AUTOSAR XML (schema 3.1.2)
package /Components/SWC_AFAMgtT
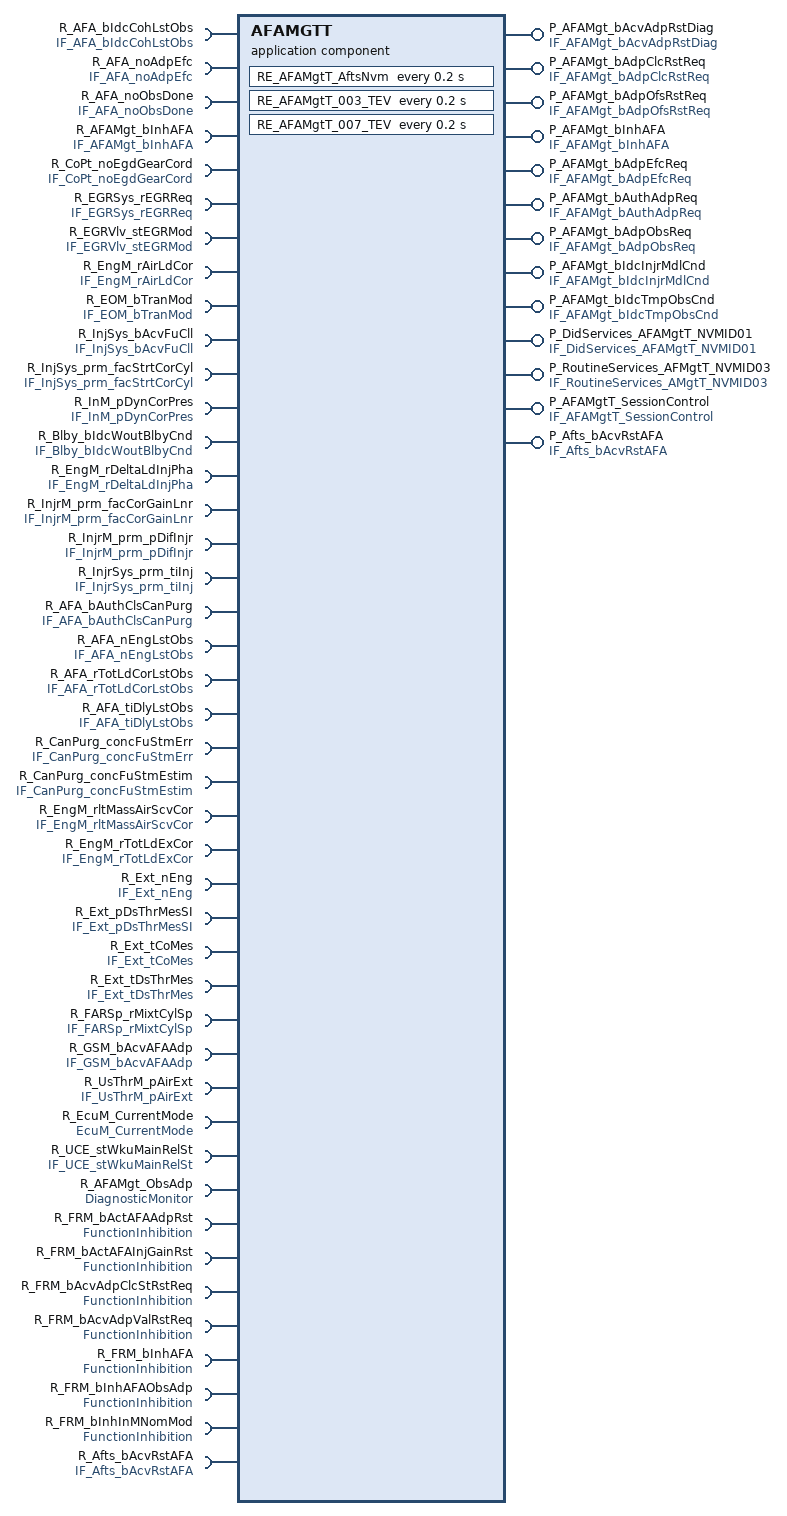
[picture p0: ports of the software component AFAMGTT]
  application software component type AFAMGTT
    42 x require port:
      R_AFA_bIdcCohLstObs: unqueued-receiver-com-spec{data-element=AFA_bIdcCohLstObs, init-value=AFA_bIdcCohLstObs_Cst, resync-time=0}, required-interface=IF_AFA_bIdcCohLstObs  # Receiver of interface IF_AFA_bIdcCohLstObs - Requirement Reference: [01552_10_03370-AFAMgtT-I016(0)]
      R_AFA_noAdpEfc: unqueued-receiver-com-spec{data-element=AFA_noAdpEfc, init-value=AFA_noAdpEfc_Cst, resync-time=0}, required-interface=IF_AFA_noAdpEfc  # Receiver of interface IF_AFA_noAdpEfc - Requirement Reference: [01552_10_03370-AFAMgtT-I017(0)]
      R_AFA_noObsDone: unqueued-receiver-com-spec{data-element=AFA_noObsDone, init-value=AFA_noObsDone_Cst, resync-time=0}, required-interface=IF_AFA_noObsDone  # Receiver of interface IF_AFA_noObsDone - Requirement Reference: [01552_10_03370-AFAMgtT-I018(0)]
      R_AFAMgt_bInhAFA: unqueued-receiver-com-spec{data-element=AFAMgt_bInhAFA, init-value=AFAMgt_bInhAFA_Cst, resync-time=0}, required-interface=IF_AFAMgt_bInhAFA  # Receiver of interface IF_AFAMgt_bInhAFA - Requirement Reference: [01552_10_03370-AFAMgtT-I028(0)]
      R_CoPt_noEgdGearCord: unqueued-receiver-com-spec{data-element=CoPt_noEgdGearCord, init-value=CoPt_noEgdGearCord_Cst, resync-time=0}, required-interface=IF_CoPt_noEgdGearCord  # Receiver of interface IF_CoPt_noEgdGearCord - Requirement Reference: [01552_10_03370-AFAMgtT-I035(0)]
      R_EGRSys_rEGRReq: unqueued-receiver-com-spec{data-element=EGRSys_rEGRReq, init-value=EGRSys_rEGRReq_Cst, resync-time=0}, required-interface=IF_EGRSys_rEGRReq  # Receiver of interface IF_EGRSys_rEGRReq - Requirement Reference: [01552_10_03370-AFAMgtT-I036(0)]
      R_EGRVlv_stEGRMod: unqueued-receiver-com-spec{data-element=EGRVlv_stEGRMod, init-value=EGRVlv_stEGRMod_Cst, resync-time=0}, required-interface=IF_EGRVlv_stEGRMod  # Receiver of interface IF_EGRVlv_stEGRMod - Requirement Reference: [01552_10_03370-AFAMgtT-I037(0)]
      R_EngM_rAirLdCor: unqueued-receiver-com-spec{data-element=EngM_rAirLdCor, init-value=EngM_rAirLdCor_Cst, resync-time=0}, required-interface=IF_EngM_rAirLdCor  # Receiver of interface IF_EngM_rAirLdCor - Requirement Reference: [01552_10_03370-AFAMgtT-I038(0)]
      R_EOM_bTranMod: unqueued-receiver-com-spec{data-element=EOM_bTranMod, init-value=EOM_bTranMod_Cst, resync-time=0}, required-interface=IF_EOM_bTranMod  # Receiver of interface IF_EOM_bTranMod - Requirement Reference: [01552_10_03370-AFAMgtT-I039(0)]
      R_InjSys_bAcvFuCll: unqueued-receiver-com-spec{data-element=InjSys_bAcvFuCll, init-value=InjSys_bAcvFuCll_Cst, resync-time=0}, required-interface=IF_InjSys_bAcvFuCll  # Receiver of interface IF_InjSys_bAcvFuCll - Requirement Reference: [01552_10_03370-AFAMgtT-I040(0)]
      R_InjSys_prm_facStrtCorCyl: unqueued-receiver-com-spec{data-element=InjSys_prm_facStrtCorCyl, init-value=InjSys_prm_facStrtCorCyl_Cst, resync-time=0}, required-interface=IF_InjSys_prm_facStrtCorCyl  # Receiver of interface IF_InjSys_prm_facStrtCorCyl - Requirement Reference: [01552_10_03370-AFAMgtT-I041(0)]
      R_InM_pDynCorPres: unqueued-receiver-com-spec{data-element=InM_pDynCorPres, init-value=InM_pDynCorPres_Cst, resync-time=0}, required-interface=IF_InM_pDynCorPres  # Receiver of interface IF_InM_pDynCorPres - Requirement Reference: [01552_10_03370-AFAMgtT-I042(0)]
      R_Blby_bIdcWoutBlbyCnd: unqueued-receiver-com-spec{data-element=Blby_bIdcWoutBlbyCnd, init-value=Blby_bIdcWoutBlbyCnd_Cst, resync-time=0}, required-interface=IF_Blby_bIdcWoutBlbyCnd  # Receiver of interface IF_Blby_bIdcWoutBlbyCnd - Requirement Reference: [01552_10_03370-AFAMgtT-I047(0)]
      R_EngM_rDeltaLdInjPha: unqueued-receiver-com-spec{data-element=EngM_rDeltaLdInjPha, init-value=EngM_rDeltaLdInjPha_Cst, resync-time=0}, required-interface=IF_EngM_rDeltaLdInjPha  # Receiver of interface IF_EngM_rDeltaLdInjPha - Requirement Reference: [01552_10_03370-AFAMgtT-I048(1)]
      R_InjrM_prm_facCorGainLnr: unqueued-receiver-com-spec{data-element=InjrM_prm_facCorGainLnr, init-value=InjrM_prm_facCorGainLnr_Cst, resync-time=0}, required-interface=IF_InjrM_prm_facCorGainLnr  # Receiver of interface IF_InjrM_prm_facCorGainLnr - Requirement Reference: [01552_10_03370-AFAMgtT-I049(0)]
      R_InjrM_prm_pDifInjr: unqueued-receiver-com-spec{data-element=InjrM_prm_pDifInjr, init-value=InjrM_prm_pDifInjr_Cst, resync-time=0}, required-interface=IF_InjrM_prm_pDifInjr  # Receiver of interface IF_InjrM_prm_pDifInjr - Requirement Reference: [01552_10_03370-AFAMgtT-I050(0)]
      R_InjrSys_prm_tiInj: unqueued-receiver-com-spec{data-element=InjrSys_prm_tiInj, init-value=InjrSys_prm_tiInj_Cst, resync-time=0}, required-interface=IF_InjrSys_prm_tiInj  # Receiver of interface IF_InjrSys_prm_tiInj - Requirement Reference: [01552_10_03370-AFAMgtT-I051(1)]
      R_AFA_bAuthClsCanPurg: unqueued-receiver-com-spec{data-element=AFA_bAuthClsCanPurg, init-value=AFA_bAuthClsCanPurg_Cst, resync-time=0}, required-interface=IF_AFA_bAuthClsCanPurg  # Receiver of interface IF_AFA_bAuthClsCanPurg - Requirement Reference: [01552_10_03370-AFAMgtT-I052(0)]
      R_AFA_nEngLstObs: unqueued-receiver-com-spec{data-element=AFA_nEngLstObs, init-value=AFA_nEngLstObs_Cst, resync-time=0}, required-interface=IF_AFA_nEngLstObs  # Receiver of interface IF_AFA_nEngLstObs - Requirement Reference: [01552_10_03370-AFAMgtT-I053(0)]
      R_AFA_rTotLdCorLstObs: unqueued-receiver-com-spec{data-element=AFA_rTotLdCorLstObs, init-value=AFA_rTotLdCorLstObs_Cst, resync-time=0}, required-interface=IF_AFA_rTotLdCorLstObs  # Receiver of interface IF_AFA_rTotLdCorLstObs - Requirement Reference: [01552_10_03370-AFAMgtT-I054(0)]
      R_AFA_tiDlyLstObs: unqueued-receiver-com-spec{data-element=AFA_tiDlyLstObs, init-value=AFA_tiDlyLstObs_Cst, resync-time=0}, required-interface=IF_AFA_tiDlyLstObs  # Receiver of interface IF_AFA_tiDlyLstObs - Requirement Reference: [01552_10_03370-AFAMgtT-I055(1)]
      R_CanPurg_concFuStmErr: unqueued-receiver-com-spec{data-element=CanPurg_concFuStmErr, init-value=CanPurg_concFuStmErr_Cst, resync-time=0}, required-interface=IF_CanPurg_concFuStmErr  # Receiver of interface IF_CanPurg_concFuStmErr - Requirement Reference: [01552_10_03370-AFAMgtT-I067(0)]
      R_CanPurg_concFuStmEstim: unqueued-receiver-com-spec{data-element=CanPurg_concFuStmEstim, init-value=CanPurg_concFuStmEstim_Cst, resync-time=0}, required-interface=IF_CanPurg_concFuStmEstim  # Receiver of interface IF_CanPurg_concFuStmEstim - Requirement Reference: [01552_10_03370-AFAMgtT-I068(0)]
      R_EngM_rltMassAirScvCor: unqueued-receiver-com-spec{data-element=EngM_rltMassAirScvCor, init-value=EngM_rltMassAirScvCor_Cst, resync-time=0}, required-interface=IF_EngM_rltMassAirScvCor  # Receiver of interface IF_EngM_rltMassAirScvCor - Requirement Reference: [01552_10_03370-AFAMgtT-I069(0)]
      R_EngM_rTotLdExCor: unqueued-receiver-com-spec{data-element=EngM_rTotLdExCor, init-value=EngM_rTotLdExCor_Cst, resync-time=0}, required-interface=IF_EngM_rTotLdExCor  # Receiver of interface IF_EngM_rTotLdExCor - Requirement Reference: [01552_10_03370-AFAMgtT-I070(0)]
      R_Ext_nEng: unqueued-receiver-com-spec{data-element=Ext_nEng, init-value=Ext_nEng_Cst, resync-time=0}, required-interface=IF_Ext_nEng  # Receiver of interface IF_Ext_nEng - Requirement Reference: [01552_10_03370-AFAMgtT-I071(0)]
      R_Ext_pDsThrMesSI: unqueued-receiver-com-spec{data-element=Ext_pDsThrMesSI, init-value=Ext_pDsThrMesSI_Cst, resync-time=0}, required-interface=IF_Ext_pDsThrMesSI  # Receiver of interface IF_Ext_pDsThrMesSI - Requirement Reference: [01552_10_03370-AFAMgtT-I072(0)]
      R_Ext_tCoMes: unqueued-receiver-com-spec{data-element=Ext_tCoMes, init-value=Ext_tCoMes_Cst, resync-time=0}, required-interface=IF_Ext_tCoMes  # Receiver of interface IF_Ext_tCoMes - Requirement Reference: [01552_10_03370-AFAMgtT-I073(0)]
      R_Ext_tDsThrMes: unqueued-receiver-com-spec{data-element=Ext_tDsThrMes, init-value=Ext_tDsThrMes_Cst, resync-time=0}, required-interface=IF_Ext_tDsThrMes  # Receiver of interface IF_Ext_tDsThrMes - Requirement Reference: [01552_10_03370-AFAMgtT-I074(0)]
      R_FARSp_rMixtCylSp: unqueued-receiver-com-spec{data-element=FARSp_rMixtCylSp, init-value=FARSp_rMixtCylSp_Cst, resync-time=0}, required-interface=IF_FARSp_rMixtCylSp  # Receiver of interface IF_FARSp_rMixtCylSp - Requirement Reference: [01552_10_03370-AFAMgtT-I075(0)]
      R_GSM_bAcvAFAAdp: unqueued-receiver-com-spec{data-element=GSM_bAcvAFAAdp, init-value=GSM_bAcvAFAAdp_Cst, resync-time=0}, required-interface=IF_GSM_bAcvAFAAdp  # Receiver of interface IF_GSM_bAcvAFAAdp - Requirement Reference: [01552_10_03370-AFAMgtT-I076(0)]
      R_UsThrM_pAirExt: unqueued-receiver-com-spec{data-element=UsThrM_pAirExt, init-value=UsThrM_pAirExt_Cst, resync-time=0}, required-interface=IF_UsThrM_pAirExt  # Receiver of interface IF_UsThrM_pAirExt - Requirement Reference: [01552_10_03370-AFAMgtT-I077(0)]
      R_EcuM_CurrentMode: required-interface=EcuM_CurrentMode
      R_UCE_stWkuMainRelSt: required-interface=IF_UCE_stWkuMainRelSt
      R_AFAMgt_ObsAdp: required-interface=DiagnosticMonitor  # 01552_10_03370-AFAMgtT-I093(1)
      R_FRM_bActAFAAdpRst: required-interface=FunctionInhibition  # 01552_10_03370-AFAMgtT-I087(1)
      R_FRM_bActAFAInjGainRst: required-interface=FunctionInhibition  # 01552_10_03370-AFAMgtT-I088(1)
      R_FRM_bAcvAdpClcStRstReq: required-interface=FunctionInhibition  # 01552_10_03370-AFAMgtT-I089(1)
      R_FRM_bAcvAdpValRstReq: required-interface=FunctionInhibition  # 01552_10_03370-AFAMgtT-I090(1)
      R_FRM_bInhAFA: required-interface=FunctionInhibition  # 01552_10_03370-AFAMgtT-I091(1)
      R_FRM_bInhAFAObsAdp: required-interface=FunctionInhibition  # 01552_10_03370-AFAMgtT-I094(1)
      R_FRM_bInhInMNomMod: required-interface=FunctionInhibition  # 01552_10_03370-AFAMgtT-I092(1)
    13 x provide port:
      P_AFAMgt_bAcvAdpRstDiag: unqueued-sender-com-spec{data-element=AFAMgt_bAcvAdpRstDiag, can-invalidate=false, init-value=AFAMgt_bAcvAdpRstDiag_Cst}, provided-interface=IF_AFAMgt_bAcvAdpRstDiag
      P_AFAMgt_bAdpClcRstReq: unqueued-sender-com-spec{data-element=AFAMgt_bAdpClcRstReq, can-invalidate=false, init-value=AFAMgt_bAdpClcRstReq_Cst}, provided-interface=IF_AFAMgt_bAdpClcRstReq
      P_AFAMgt_bAdpOfsRstReq: unqueued-sender-com-spec{data-element=AFAMgt_bAdpOfsRstReq, can-invalidate=false, init-value=AFAMgt_bAdpOfsRstReq_Cst}, provided-interface=IF_AFAMgt_bAdpOfsRstReq
      P_AFAMgt_bInhAFA: unqueued-sender-com-spec{data-element=AFAMgt_bInhAFA, can-invalidate=false, init-value=AFAMgt_bInhAFA_Cst}, provided-interface=IF_AFAMgt_bInhAFA
      P_AFAMgt_bAdpEfcReq: unqueued-sender-com-spec{data-element=AFAMgt_bAdpEfcReq, can-invalidate=false, init-value=AFAMgt_bAdpEfcReq_Cst}, provided-interface=IF_AFAMgt_bAdpEfcReq
      P_AFAMgt_bAuthAdpReq: unqueued-sender-com-spec{data-element=AFAMgt_bAuthAdpReq, can-invalidate=false, init-value=AFAMgt_bAuthAdpReq_Cst}, provided-interface=IF_AFAMgt_bAuthAdpReq
      P_AFAMgt_bAdpObsReq: unqueued-sender-com-spec{data-element=AFAMgt_bAdpObsReq, can-invalidate=false, init-value=AFAMgt_bAdpObsReq_Cst}, provided-interface=IF_AFAMgt_bAdpObsReq
      P_AFAMgt_bIdcInjrMdlCnd: unqueued-sender-com-spec{data-element=AFAMgt_bIdcInjrMdlCnd, can-invalidate=false, init-value=AFAMgt_bIdcInjrMdlCnd_Cst}, provided-interface=IF_AFAMgt_bIdcInjrMdlCnd
      P_AFAMgt_bIdcTmpObsCnd: unqueued-sender-com-spec{data-element=AFAMgt_bIdcTmpObsCnd, can-invalidate=false, init-value=AFAMgt_bIdcTmpObsCnd_Cst}, provided-interface=IF_AFAMgt_bIdcTmpObsCnd
      P_DidServices_AFAMgtT_NVMID01: provided-interface=IF_DidServices_AFAMgtT_NVMID01
        provided-com-specs:
          operation=ConditionCheckWrite, queue-length=1
          operation=ReadDataLength, queue-length=1
          operation=ReadData, queue-length=1
          operation=ConditionCheckRead, queue-length=1
          operation=WriteData, queue-length=1
      P_RoutineServices_AFMgtT_NVMID03: provided-com-specs=[{operation=RequestResults, queue-length=1}, {operation=Start, queue-length=1}], provided-interface=IF_RoutineServices_AMgtT_NVMID03
      P_AFAMgtT_SessionControl: provided-com-specs=[{operation=GetSesChgPermission, queue-length=1}, {operation=ChangeIndication, queue-length=1}], provided-interface=IF_AFAMgtT_SessionControl
      P_Afts_bAcvRstAFA: unqueued-sender-com-spec{data-element=Afts_bAcvRstAFA, can-invalidate=false, init-value=Afts_bAcvRstAFA_Cst}, provided-interface=IF_Afts_bAcvRstAFA
    require port R_Afts_bAcvRstAFA: unqueued-receiver-com-spec{data-element=Afts_bAcvRstAFA, init-value=Afts_bAcvRstAFA_Cst, resync-time=0}, required-interface=IF_Afts_bAcvRstAFA
  71 x constant specification:
    AFA_bAuthClsCanPurg_Cst
      value:
        boolean literal AFA_bAuthClsCanPurg_Cst: type=DT_AFA_bAuthClsCanPurg, value=false
    AFA_bIdcCohLstObs_Cst
      value:
        boolean literal AFA_bIdcCohLstObs_Cst: type=DT_AFA_bIdcCohLstObs, value=false
    AFA_nEngLstObs_Cst
      value:
        integer literal AFA_nEngLstObs_Cst: type=DT_AFA_nEngLstObs, value=0
    AFA_noAdpEfc_Cst
      value:
        integer literal AFA_noAdpEfc_Cst: type=DT_AFA_noAdpEfc, value=0
    AFA_noObsDone_Cst
      value:
        integer literal AFA_noObsDone_Cst: type=DT_AFA_noObsDone, value=0
    AFA_rTotLdCorLstObs_Cst
      value:
        integer literal AFA_rTotLdCorLstObs_Cst: type=DT_AFA_rTotLdCorLstObs, value=0
    AFA_tiDlyLstObs_Cst
      value:
        integer literal AFA_tiDlyLstObs_Cst: type=DT_AFA_tiDlyLstObs, value=0
    AFAMgt_bAcvAdpRstDiag_Cst
      value:
        boolean literal AFAMgt_bAcvAdpRstDiag_Cst: type=DT_AFAMgt_bAcvAdpRstDiag, value=false
    AFAMgt_bAdpClcRstReq_Cst
      value:
        boolean literal AFAMgt_bAdpClcRstReq_Cst: type=DT_AFAMgt_bAdpClcRstReq, value=false
    AFAMgt_bAdpEfcReq_Cst
      value:
        boolean literal AFAMgt_bAdpEfcReq_Cst: type=DT_AFAMgt_bAdpEfcReq, value=false
    AFAMgt_bAdpObsReq_Cst
      value:
        boolean literal AFAMgt_bAdpObsReq_Cst: type=DT_AFAMgt_bAdpObsReq, value=false
    AFAMgt_bAdpOfsRstReq_Cst
      value:
        boolean literal AFAMgt_bAdpOfsRstReq_Cst: type=DT_AFAMgt_bAdpOfsRstReq, value=false
    AFAMgt_bAuthAdpReq_Cst
      value:
        boolean literal AFAMgt_bAuthAdpReq_Cst: type=DT_AFAMgt_bAuthAdpReq, value=false
    AFAMgt_bEveRstStabChk_irv_Cst
      value:
        boolean literal AFAMgt_bEveRstStabChk_irv_Cst: type=DT_AFAMgt_bEveRstStabChk_irv, value=false
    AFAMgt_bIdcInjrMdlCnd_Cst
      value:
        boolean literal AFAMgt_bIdcInjrMdlCnd_Cst: type=DT_AFAMgt_bIdcInjrMdlCnd, value=false
    AFAMgt_bIdcNotDynCorPres_irv_Cst
      value:
        boolean literal AFAMgt_bIdcNotDynCorPres_irv_Cst: type=DT_AFAMgt_bIdcNotDynCorPres_irv, value=false
    AFAMgt_bIdcStabAirMod_irv_Cst
      value:
        boolean literal AFAMgt_bIdcStabAirMod_irv_Cst: type=DT_AFAMgt_bIdcStabAirMod_irv, value=false
    AFAMgt_bIdcStabFuMod_irv_Cst
      value:
        boolean literal AFAMgt_bIdcStabFuMod_irv_Cst: type=DT_AFAMgt_bIdcStabFuMod_irv, value=false
    AFAMgt_bIdcStabRatOpEGR_irv_Cst
      value:
        boolean literal AFAMgt_bIdcStabRatOpEGR_irv_Cst: type=DT_AFAMgt_bIdcStabRatOpEGR_irv, value=false
    AFAMgt_bIdcTmpObsCnd_Cst
      value:
        boolean literal AFAMgt_bIdcTmpObsCnd_Cst: type=DT_AFAMgt_bIdcTmpObsCnd, value=false
    AFAMgt_bInhAFA_Cst
      value:
        boolean literal AFAMgt_bInhAFA_Cst: type=DT_AFAMgt_bInhAFA, value=false
    AFAMgt_bInhAirModTmp_irv_Cst
      value:
        boolean literal AFAMgt_bInhAirModTmp_irv_Cst: type=DT_AFAMgt_bInhAirModTmp_irv, value=false
    AFAMgt_bStabAirLdCor_irv_Cst
      value:
        boolean literal AFAMgt_bStabAirLdCor_irv_Cst: type=DT_AFAMgt_bStabAirLdCor_irv, value=false
    AFAMgt_bStabEgdGear_irv_Cst
      value:
        boolean literal AFAMgt_bStabEgdGear_irv_Cst: type=DT_AFAMgt_bStabEgdGear_irv, value=false
    AFAMgt_bStabEOM_irv_Cst
      value:
        boolean literal AFAMgt_bStabEOM_irv_Cst: type=DT_AFAMgt_bStabEOM_irv, value=false
    AFAMgt_bStabFacStrtCor_irv_Cst
      value:
        boolean literal AFAMgt_bStabFacStrtCor_irv_Cst: type=DT_AFAMgt_bStabFacStrtCor_irv, value=false
    AFAMgt_bTranModHld_irv_Cst
      value:
        boolean literal AFAMgt_bTranModHld_irv_Cst: type=DT_AFAMgt_bTranModHld_irv, value=false
    AFAMgt_noEgdGearCordHld_irv_Cst
      value:
        integer literal AFAMgt_noEgdGearCordHld_irv_Cst: type=DT_AFAMgt_noEgdGearCordHld_irv, value=0
    AFAMgt_rAirLdMax_irv_Cst
      value:
        integer literal AFAMgt_rAirLdMax_irv_Cst: type=DT_AFAMgt_rAirLdMax_irv, value=0
    AFAMgt_rAirLdMin_irv_Cst
      value:
        integer literal AFAMgt_rAirLdMin_irv_Cst: type=DT_AFAMgt_rAirLdMin_irv, value=0
    AFAMgt_rEGRMax_irv_Cst
      value:
        integer literal AFAMgt_rEGRMax_irv_Cst: type=DT_AFAMgt_rEGRMax_irv, value=0
    AFAMgt_rEGRMin_irv_Cst
      value:
        integer literal AFAMgt_rEGRMin_irv_Cst: type=DT_AFAMgt_rEGRMin_irv, value=0
    AFAMgt_tiCntStabAirLd_irv_Cst
      value:
        integer literal AFAMgt_tiCntStabAirLd_irv_Cst: type=DT_AFAMgt_tiCntStabAirLd_irv, value=0
    AFAMgt_tiCntStabAirMod_irv_Cst
      value:
        integer literal AFAMgt_tiCntStabAirMod_irv_Cst: type=DT_AFAMgt_tiCntStabAirMod_irv, value=0
    AFAMgt_tiCntStabEgdGear_irv_Cst
      value:
        integer literal AFAMgt_tiCntStabEgdGear_irv_Cst: type=DT_AFAMgt_tiCntStabEgdGear_irv, value=0
    AFAMgt_tiCntStabEOM_irv_Cst
      value:
        integer literal AFAMgt_tiCntStabEOM_irv_Cst: type=DT_AFAMgt_tiCntStabEOM_irv, value=0
    AFAMgt_tiCntStabFacStrt_irv_Cst
      value:
        integer literal AFAMgt_tiCntStabFacStrt_irv_Cst: type=DT_AFAMgt_tiCntStabFacStrt_irv, value=0
    AFAMgt_tiCntStabFuMod_irv_Cst
      value:
        integer literal AFAMgt_tiCntStabFuMod_irv_Cst: type=DT_AFAMgt_tiCntStabFuMod_irv, value=0
    AFAMgt_tiCntStabRatOpEGR_irv_Cst
      value:
        integer literal AFAMgt_tiCntStabRatOpEGR_irv_Cst: type=DT_AFAMgt_tiCntStabRatOpEGR_irv, value=0
    AFAMgt_tiDlyLstObsThd_irv_Cst
      value:
        integer literal AFAMgt_tiDlyLstObsThd_irv_Cst: type=DT_AFAMgt_tiDlyLstObsThd_irv, value=0
    AFAMgtT_ctLockRqAftsNvm_Cst
      value:
        integer literal AFAMgtT_ctLockRqAftsNvm_Cst: type=DT_AFAMgtT_ctLockRqAftsNvm, value=0
    AFAMgtT_IDAftsNvm_Cst
      value:
        integer literal AFAMgtT_IDAftsNvm_Cst: type=DT_AFAMgtT_IDAftsNvm, value=0
    AFAMgtT_LockedAftsNvm_Cst
      value:
        boolean literal AFAMgtT_LockedAftsNvm_Cst: type=DT_AFAMgtT_LockedAftsNvm, value=false
    AFAMgtT_stAftsNvm_Cst
      value:
        integer literal AFAMgtT_stAftsNvm_Cst: type=DT_AFAMgtT_stAftsNvm, value=0
    AFAMgtT_stRstNvmRtn_Cst
      value:
        integer literal AFAMgtT_stRstNvmRtn_Cst: type=DT_AFAMgtT_stRstNvmRtn, value=0
    AFMgt_tiCntNotDynCorPres_irv_Cst
      value:
        integer literal AFMgt_tiCntNotDynCorPres_irv_Cst: type=DT_AFAMgt_tiCntNotDynCorPres_irv, value=0
    Afts_bAcvRstAFA_Cst
      value:
        boolean literal Afts_bAcvRstAFA_Cst: type=DT_Afts_bAcvRstAFA, value=false
    Blby_bIdcWoutBlbyCnd_Cst
      value:
        boolean literal Blby_bIdcWoutBlbyCnd_Cst: type=DT_Blby_bIdcWoutBlbyCnd, value=false
    CanPurg_concFuStmErr_Cst
      value:
        integer literal CanPurg_concFuStmErr_Cst: type=DT_CanPurg_concFuStmErr, value=0
    CanPurg_concFuStmEstim_Cst
      value:
        integer literal CanPurg_concFuStmEstim_Cst: type=DT_CanPurg_concFuStmEstim, value=0
    CoPt_noEgdGearCord_Cst
      value:
        integer literal CoPt_noEgdGearCord_Cst: type=DT_CoPt_noEgdGearCord, value=0
    EGRSys_rEGRReq_Cst
      value:
        integer literal EGRSys_rEGRReq_Cst: type=DT_EGRSys_rEGRReq, value=0
    EGRVlv_stEGRMod_Cst
      value:
        integer literal EGRVlv_stEGRMod_Cst: type=DT_EGRVlv_stEGRMod, value=1
    EngM_rAirLdCor_Cst
      value:
        integer literal EngM_rAirLdCor_Cst: type=DT_EngM_rAirLdCor, value=0
    EngM_rDeltaLdInjPha_Cst
      value:
        integer literal EngM_rDeltaLdInjPha_Cst: type=DT_EngM_rDeltaLdInjPha, value=0
    EngM_rltMassAirScvCor_Cst
      value:
        integer literal EngM_rltMassAirScvCor_Cst: type=DT_EngM_rltMassAirScvCor, value=0
    EngM_rTotLdExCor_Cst
      value:
        integer literal EngM_rTotLdExCor_Cst: type=DT_EngM_rTotLdExCor, value=0
    EOM_bTranMod_Cst
      value:
        boolean literal EOM_bTranMod_Cst: type=DT_EOM_bTranMod, value=false
    Ext_nEng_Cst
      value:
        integer literal Ext_nEng_Cst: type=DT_Ext_nEng, value=0
    Ext_pDsThrMesSI_Cst
      value:
        integer literal Ext_pDsThrMesSI_Cst: type=DT_Ext_pDsThrMesSI, value=1875
    Ext_tCoMes_Cst
      value:
        integer literal Ext_tCoMes_Cst: type=DT_Ext_tCoMes, value=20
    Ext_tDsThrMes_Cst
      value:
        integer literal Ext_tDsThrMes_Cst: type=DT_Ext_tDsThrMes, value=25
    FARSp_rMixtCylSp_Cst
      value:
        integer literal FARSp_rMixtCylSp_Cst: type=DT_FARSp_rMixtCylSp, value=4096
    GSM_bAcvAFAAdp_Cst
      value:
        boolean literal GSM_bAcvAFAAdp_Cst: type=DT_GSM_bAcvAFAAdp, value=false
    InjrM_prm_facCorGainLnr_Cst
      value:
        array specification InjrM_prm_facCorGainLnr_Cst: type=rt_Array_UInt16_4_m3
          4 x integer literal, all with type=DT_InjrM_prm_facCorGainLnr, value=0:
            Element_{0..3}
    InjrM_prm_pDifInjr_Cst
      value:
        array specification InjrM_prm_pDifInjr_Cst: type=rt_Array_UInt16_4_m4
          4 x integer literal, all with type=DT_InjrM_prm_pDifInjr, value=0:
            Element_{0..3}
    InjrSys_prm_tiInj_Cst
      value:
        array specification InjrSys_prm_tiInj_Cst: type=Array_4_UInt32
          4 x integer literal, all with type=DT_InjrSys_prm_tiInj, value=0:
            Element_{0..3}
    InjSys_bAcvFuCll_Cst
      value:
        boolean literal InjSys_bAcvFuCll_Cst: type=DT_InjSys_bAcvFuCll, value=false
    InjSys_prm_facStrtCorCyl_Cst
      value:
        array specification InjSys_prm_facStrtCorCyl_Cst: type=Array_6_UInt16_m1
          6 x integer literal, all with type=DT_InjSys_prm_facStrtCorCyl, value=0:
            Element_{0..5}
    InM_pDynCorPres_Cst
      value:
        integer literal InM_pDynCorPres_Cst: type=DT_InM_pDynCorPres, value=0
    UsThrM_pAirExt_Cst
      value:
        integer literal UsThrM_pAirExt_Cst: type=DT_UsThrM_pAirExt, value=0
  internal behavior IB_AFAMgtT: component=AFAMGTT
    7 x operation invoked event:
      EV_AFAMgtT_AftsSesChgInd: start-on-event=RE_AFAMgtT_AftsSesChgInd, operation=P_AFAMgtT_SessionControl.ChangeIndication
      EV_AFMgtT_AftsNvmChkRead_NVMID01: start-on-event=RE_AFAMgtT_AftsNvmChkRead, operation=P_DidServices_AFAMgtT_NVMID01.ConditionCheckRead
      EV_AFAMgtT_AftsNvmRDL_NVMID01: start-on-event=RE_AFAMgtT_AftsNvmRDL, operation=P_DidServices_AFAMgtT_NVMID01.ReadDataLength
      EV_AFAMgtT_RstStart_NVMID03: start-on-event=RE_AFAMgtT_RstStart, operation=P_RoutineServices_AFMgtT_NVMID03.Start
      EV_AFAMgtT_AftsNvmRead_NVMID01: start-on-event=RE_AFAMgtT_AftsNvmRead, operation=P_DidServices_AFAMgtT_NVMID01.ReadData
      EV_AFAMgtT_AftsGetSesChgPerm: start-on-event=RE_AFAMgtT_AftsGetSesChgPerm, operation=P_AFAMgtT_SessionControl.GetSesChgPermission
      EV_AFAMgtT_AftsNvmWrite_NVMID01: start-on-event=RE_AFAMgtT_AftsNvmWrite, operation=P_DidServices_AFAMgtT_NVMID01.WriteData
    mode switch event EV_AFAMgtT_001_MSE: start-on-event=RE_AFAMgtT_001_MSE, activation=ENTRY, mode=R_EcuM_CurrentMode.currentMode.RUN
    operation invoked event EV_AMgtT_AftsNvmChkWrite_NVMID01: start-on-event=RE_AFAMgtT_AftsNvmChkWrite, operation=P_DidServices_AFAMgtT_NVMID01.ConditionCheckWrite
    timing event EV_AFAMgtT_AftsNvm: mode-dependency=dependent-on-mode=[R_UCE_stWkuMainRelSt.RCD_stWkuMainRelSt.Invalid, R_UCE_stWkuMainRelSt.RCD_stWkuMainRelSt.PostMainWakeUp, R_UCE_stWkuMainRelSt.RCD_stWkuMainRelSt.PreMainWakeUp], start-on-event=RE_AFAMgtT_AftsNvm, period=0.2
    mode switch event EV_AFAMgtT_AftrsInit: start-on-event=RE_AFAMgtT_AftrsInit, activation=ENTRY, mode=R_EcuM_CurrentMode.currentMode.RUN
    mode switch event EV_AFAMgtT_002_MSE: start-on-event=RE_AFAMgtT_002_MSE, activation=ENTRY, mode=R_EcuM_CurrentMode.currentMode.RUN
    timing event EV_AFAMgtT_003_TEV: mode-dependency=dependent-on-mode=[R_UCE_stWkuMainRelSt.RCD_stWkuMainRelSt.Invalid, R_UCE_stWkuMainRelSt.RCD_stWkuMainRelSt.PostMainWakeUp, R_UCE_stWkuMainRelSt.RCD_stWkuMainRelSt.PreMainWakeUp], start-on-event=RE_AFAMgtT_003_TEV, period=0.2
    timing event EV_AFAMgtT_007_TEV: mode-dependency=dependent-on-mode=[R_UCE_stWkuMainRelSt.RCD_stWkuMainRelSt.Invalid, R_UCE_stWkuMainRelSt.RCD_stWkuMainRelSt.PostMainWakeUp, R_UCE_stWkuMainRelSt.RCD_stWkuMainRelSt.PreMainWakeUp], start-on-event=RE_AFAMgtT_007_TEV, period=0.2
    mode switch event EV_AFAMgtT_004_MSE: start-on-event=RE_AFAMgtT_004_MSE, activation=ENTRY, mode=R_EcuM_CurrentMode.currentMode.RUN
    operation invoked event EV_AFAMgtT_RstRqResults_NVMID03: start-on-event=RE_AFAMgtT_RstRqResults, operation=P_RoutineServices_AFMgtT_NVMID03.RequestResults
    30 x inter runnable variable, all with sw-calibration-access=READ-WRITE, communication-approach=EXPLICIT:
      AFAMgt_tiCntStabAirMod_irv: type=DT_AFAMgt_tiCntStabAirMod_irv, init-value=AFAMgt_tiCntStabAirMod_irv_Cst  # [01552_10_03370-AFAMgtT-I107(3)] - Compteur de temps pour la stabilité du mode de fonctionnement air
      AFAMgt_bIdcNotDynCorPres_irv: type=DT_AFAMgt_bIdcNotDynCorPres_irv, init-value=AFAMgt_bIdcNotDynCorPres_irv_Cst  # [01552_10_03370-AFAMgtT-I056(2)] - Indicateur d'absence de correction dynamique de pression
      AFAMgt_tiCntStabFuMod_irv: type=DT_AFAMgt_tiCntStabFuMod_irv, init-value=AFAMgt_tiCntStabFuMod_irv_Cst  # [01552_10_03370-AFAMgtT-I106(3)] - Compteur de temps pour la stabilité du mode de fonctionnement essence
      AFAMgt_tiCntStabEgdGear_irv: type=DT_AFAMgt_tiCntStabEgdGear_irv, init-value=AFAMgt_tiCntStabEgdGear_irv_Cst  # [01552_10_03370-AFAMgtT-I100(3)] - Compteur de temps pour la stabilité du rapport de vitesse
      AFAMgt_rAirLdMax_irv: type=DT_AFAMgt_rAirLdMax_irv, init-value=AFAMgt_rAirLdMax_irv_Cst  # [01552_10_03370-AFAMgtT-I095(2)] - Valeur maximale de la charge en air
      AFAMgt_bStabFacStrtCor_irv: type=DT_AFAMgt_bStabFacStrtCor_irv, init-value=AFAMgt_bStabFacStrtCor_irv_Cst  # [01552_10_03370-AFAMgtT-I063(2)] - indicateur de stabilité des compensations d'essence
      AFAMgt_tiDlyLstObsThd_irv: type=DT_AFAMgt_tiDlyLstObsThd_irv, init-value=AFAMgt_tiDlyLstObsThd_irv_Cst  # [01552_10_03370-AFAMgtT-I113(2)] - Délai d'attente entre les observations
      AFAMgtT_stRstNvmRtn: type=DT_AFAMgtT_stRstNvmRtn, init-value=AFAMgtT_stRstNvmRtn_Cst  # [01552_10_03370-AFAMgtT-I123(0)] - status of the corresponding routine service
      AFAMgt_tiCntNotDynCorPres_irv: type=DT_AFAMgt_tiCntNotDynCorPres_irv, init-value=AFMgt_tiCntNotDynCorPres_irv_Cst  # [01552_10_03370-AFAMgtT-I115(2)] - Compteur de temps pour l'absence de correction dynamique de pression
      AFAMgt_rAirLdMin_irv: type=DT_AFAMgt_rAirLdMin_irv, init-value=AFAMgt_rAirLdMin_irv_Cst  # [01552_10_03370-AFAMgtT-I096(2)] - Valeur minimale de la charge en air
      AFAMgt_rEGRMin_irv: type=DT_AFAMgt_rEGRMin_irv, init-value=AFAMgt_rEGRMin_irv_Cst  # [01552_10_03370-AFAMgtT-I111(2)] - Valeur minimale du taux d'EGR
      AFAMgtT_LockedAftsNvm: type=DT_AFAMgtT_LockedAftsNvm, init-value=AFAMgtT_LockedAftsNvm_Cst  # [01552_10_03370-AFAMgtT-I121(0)] - the consistency of the data is guarantee
      AFAMgt_bEveRstStabChk_irv: type=DT_AFAMgt_bEveRstStabChk_irv, init-value=AFAMgt_bEveRstStabChk_irv_Cst  # [01552_10_03370-AFAMgtT-I105(2)] - Requête d'initialisation de la fonction de vérification de la stabilité du point de fonctionnement du moteur
      AFAMgtT_stAftsNvm: type=DT_AFAMgtT_stAftsNvm, init-value=AFAMgtT_stAftsNvm_Cst  # [01552_10_03370-AFAMgtT-I119(0)] - Manage the type of aftersale service called
      AFAMgt_rEGRMax_irv: type=DT_AFAMgt_rEGRMax_irv, init-value=AFAMgt_rEGRMax_irv_Cst  # [01552_10_03370-AFAMgtT-I098(2)] - Valeur maximale du taux d'EGR
      AFAMgt_bTranModHld_irv: type=DT_AFAMgt_bTranModHld_irv, init-value=AFAMgt_bTranModHld_irv_Cst  # [01552_10_03370-AFAMgtT-I102(2)] - indicateur de transition du mode de combustion
      AFAMgt_bStabAirLdCor_irv: type=DT_AFAMgt_bStabAirLdCor_irv, init-value=AFAMgt_bStabAirLdCor_irv_Cst  # [01552_10_03370-AFAMgtT-I060(2)] - Indicateur de stabilité de la charge en air
      AFAMgt_bStabEOM_irv: type=DT_AFAMgt_bStabEOM_irv, init-value=AFAMgt_bStabEOM_irv_Cst  # [01552_10_03370-AFAMgtT-I062(2)] - indicateur de stabilité du mode de combustion
      AFAMgt_noEgdGearCordHld_irv: type=DT_AFAMgt_noEgdGearCordHld_irv, init-value=AFAMgt_noEgdGearCordHld_irv_Cst  # [01552_10_03370-AFAMgtT-I101(2)] - NS: Rapport de vitesse engagé (valeur Temporaire)
      AFAMgt_bIdcStabRatOpEGR_irv: type=DT_AFAMgt_bIdcStabRatOpEGR_irv, init-value=AFAMgt_bIdcStabRatOpEGR_irv_Cst  # [01552_10_03370-AFAMgtT-I059(2)] - Indicateur de stabilité du taux d'EGR
      AFAMgt_bIdcStabFuMod_irv: type=DT_AFAMgt_bIdcStabFuMod_irv, init-value=AFAMgt_bIdcStabFuMod_irv_Cst  # [01552_10_03370-AFAMgtT-I112(2)] - Indicateur de stabilité du mode de fonctionnement essence
      AFAMgt_tiCntStabAirLd_irv: type=DT_AFAMgt_tiCntStabAirLd_irv, init-value=AFAMgt_tiCntStabAirLd_irv_Cst  # [01552_10_03370-AFAMgtT-I097(3)] - Compteur de temps pour la stabilité de la charge en air
      AFAMgtT_IDAftsNvm: type=DT_AFAMgtT_IDAftsNvm, init-value=AFAMgtT_IDAftsNvm_Cst  # [01552_10_03370-AFAMgtT-I122(0)] - manage which NVMID to handle
      AFAMgt_bStabEgdGear_irv: type=DT_AFAMgt_bStabEgdGear_irv, init-value=AFAMgt_bStabEgdGear_irv_Cst  # [01552_10_03370-AFAMgtT-I061(2)] - Indicateur de stabilité du rapport de vitesse
      AFAMgt_tiCntStabRatOpEGR_irv: type=DT_AFAMgt_tiCntStabRatOpEGR_irv, init-value=AFAMgt_tiCntStabRatOpEGR_irv_Cst  # [01552_10_03370-AFAMgtT-I099(3)] - Compteur de temps pour la stabilité du taux d'EGR
      AFAMgtT_ctLockRqAftsNvm: type=DT_AFAMgtT_ctLockRqAftsNvm, init-value=AFAMgtT_ctLockRqAftsNvm_Cst  # [01552_10_03370-AFAMgtT-I120(0)] - guarantee the consistency of the data and support RDBI request to read several DIDs
      AFAMgt_bInhAirModTmp_irv: type=DT_AFAMgt_bInhAirModTmp_irv, init-value=AFAMgt_bInhAirModTmp_irv_Cst  # [01552_10_03370-AFAMgtT-I108(2)] - NS: Indicateur d'inhibition du mode (P,N) pour passage en (Alpha,N) (valeur Temporaire)
      AFAMgt_tiCntStabEOM_irv: type=DT_AFAMgt_tiCntStabEOM_irv, init-value=AFAMgt_tiCntStabEOM_irv_Cst  # [01552_10_03370-AFAMgtT-I103(3)] - compteur de temps pour la stabilité du mode de combustion
      AFAMgt_bIdcStabAirMod_irv: type=DT_AFAMgt_bIdcStabAirMod_irv, init-value=AFAMgt_bIdcStabAirMod_irv_Cst  # [01552_10_03370-AFAMgtT-I114(2)] - Indicateur de Stabilité du mode de fonctionnement air.
      AFAMgt_tiCntStabFacStrt_irv: type=DT_AFAMgt_tiCntStabFacStrt_irv, init-value=AFAMgt_tiCntStabFacStrt_irv_Cst  # [01552_10_03370-AFAMgtT-I104(3)] - compteur de temps pour la stabilité de non compensation d'essence
    port-api-option enable-take-address=false, indirect-api=false, port=P_RoutineServices_AFMgtT_NVMID03:
      port-arg-values:
        integer literal PAV_AFAMgtT_NVMID03: type=UInt8, value=3
    port-api-option enable-take-address=false, indirect-api=false, port=P_DidServices_AFAMgtT_NVMID01:
      port-arg-values:
        integer literal PAV_AFAMgtT_NVMID01: type=UInt8, value=1
    16 x runnable:
      RE_AFAMgtT_RstStart: read-variable=[AFAMgtT_ctLockRqAftsNvm, AFAMgtT_IDAftsNvm, AFAMgtT_stAftsNvm, AFAMgtT_stRstNvmRtn], written-variable=[AFAMgtT_ctLockRqAftsNvm, AFAMgtT_IDAftsNvm, AFAMgtT_stAftsNvm]  # 01552_10_03370-AFAMgtT-A013(0)
        data receive point dr_Ext_nEng: data-element=R_Ext_nEng.Ext_nEng
      RE_AFAMgtT_AftsSesChgInd: read-variable=AFAMgtT_stRstNvmRtn, written-variable=AFAMgtT_IDAftsNvm  # 01552_10_03370-AFAMgtT-A016(0)
      RE_AFAMgtT_AftsNvmChkRead: read-variable=[AFAMgtT_LockedAftsNvm, AFAMgtT_ctLockRqAftsNvm, AFAMgtT_stAftsNvm, AFAMgtT_IDAftsNvm, AFAMgtT_stRstNvmRtn], written-variable=[AFAMgtT_LockedAftsNvm, AFAMgtT_ctLockRqAftsNvm, AFAMgtT_stAftsNvm, AFAMgtT_IDAftsNvm]  # 01552_10_03370-AFAMgtT-A008(0)
        data receive point dr_Ext_nEng: data-element=R_Ext_nEng.Ext_nEng
      RE_AFAMgtT_AftsNvmWrite: read-variable=AFAMgtT_stAftsNvm, written-variable=AFAMgtT_stAftsNvm  # 01552_10_03370-AFAMgtT-A011(0)
      RE_AFAMgtT_AftsGetSesChgPerm  # 01552_10_03370-AFAMgtT-A015(0)
      RE_AFAMgtT_004_MSE: read-variable=[AFAMgt_rAirLdMin_irv, AFAMgt_bTranModHld_irv, AFAMgt_tiCntNotDynCorPres_irv, AFAMgt_noEgdGearCordHld_irv, AFAMgt_bInhAirModTmp_irv, AFAMgt_rEGRMin_irv, AFAMgt_rAirLdMax_irv, AFAMgt_tiCntStabEgdGear_irv, AFAMgt_rEGRMax_irv, AFAMgt_tiCntStabFacStrt_irv, AFAMgt_tiCntStabAirMod_irv, AFAMgt_tiCntStabEOM_irv, AFAMgt_tiCntStabRatOpEGR_irv, AFAMgt_tiCntStabFuMod_irv, AFAMgt_tiCntStabAirLd_irv], written-variable=[AFAMgt_rAirLdMin_irv, AFAMgt_bEveRstStabChk_irv, AFAMgt_bTranModHld_irv, AFAMgt_tiCntNotDynCorPres_irv, AFAMgt_noEgdGearCordHld_irv, AFAMgt_bStabEgdGear_irv, AFAMgt_bInhAirModTmp_irv, AFAMgt_rEGRMin_irv, AFAMgt_rAirLdMax_irv, AFAMgt_tiCntStabEgdGear_irv, AFAMgt_rEGRMax_irv, AFAMgt_bStabEOM_irv, AFAMgt_tiCntStabFacStrt_irv, AFAMgt_bIdcNotDynCorPres_irv, AFAMgt_tiCntStabAirMod_irv, AFAMgt_tiCntStabEOM_irv, AFAMgt_bStabFacStrtCor_irv, AFAMgt_bIdcStabRatOpEGR_irv, AFAMgt_tiCntStabRatOpEGR_irv, AFAMgt_bStabAirLdCor_irv, AFAMgt_bIdcStabFuMod_irv, AFAMgt_tiCntStabFuMod_irv, AFAMgt_bIdcStabAirMod_irv, AFAMgt_tiCntStabAirLd_irv]  # 01552_10_03370-AFAMgtT-A004(0)
        9 x data receive point:
          dr_InjSys_prm_facStrtCorCyl: data-element=R_InjSys_prm_facStrtCorCyl.InjSys_prm_facStrtCorCyl
          dr_EngM_rAirLdCor: data-element=R_EngM_rAirLdCor.EngM_rAirLdCor
          dr_InjSys_bAcvFuCll: data-element=R_InjSys_bAcvFuCll.InjSys_bAcvFuCll
          dr_InM_pDynCorPres: data-element=R_InM_pDynCorPres.InM_pDynCorPres
          dr_AFAMgt_bInhAFA: data-element=R_AFAMgt_bInhAFA.AFAMgt_bInhAFA
          dr_EGRSys_rEGRReq: data-element=R_EGRSys_rEGRReq.EGRSys_rEGRReq
          dr_EOM_bTranMod: data-element=R_EOM_bTranMod.EOM_bTranMod
          dr_EGRVlv_stEGRMod: data-element=R_EGRVlv_stEGRMod.EGRVlv_stEGRMod
          dr_CoPt_noEgdGearCord: data-element=R_CoPt_noEgdGearCord.CoPt_noEgdGearCord
        sync call SC_FRM_bInhInMNomMod: operation=R_FRM_bInhInMNomMod.GetFunctionPermission
      RE_AFAMgtT_AftsNvmRead: read-variable=[AFAMgtT_stAftsNvm, AFAMgtT_ctLockRqAftsNvm, AFAMgtT_LockedAftsNvm], written-variable=[AFAMgtT_stAftsNvm, AFAMgtT_ctLockRqAftsNvm, AFAMgtT_LockedAftsNvm]  # 01552_10_03370-AFAMgtT-A009(0)
      RE_AFAMgtT_AftsNvmChkWrite: read-variable=[AFAMgtT_LockedAftsNvm, AFAMgtT_IDAftsNvm, AFAMgtT_stAftsNvm, AFAMgtT_stRstNvmRtn, AFAMgtT_ctLockRqAftsNvm], written-variable=[AFAMgtT_LockedAftsNvm, AFAMgtT_IDAftsNvm, AFAMgtT_stAftsNvm, AFAMgtT_ctLockRqAftsNvm]  # 01552_10_03370-AFAMgtT-A010(0)
        data receive point dr_Ext_nEng: data-element=R_Ext_nEng.Ext_nEng
      RE_AFAMgtT_RstRqResults: read-variable=[AFAMgtT_stRstNvmRtn, AFAMgtT_IDAftsNvm, AFAMgtT_stAftsNvm], written-variable=AFAMgtT_stAftsNvm  # 01552_10_03370-AFAMgtT-A014(0)
      RE_AFAMgtT_AftsNvm: read-variable=[AFAMgtT_IDAftsNvm, AFAMgtT_ctLockRqAftsNvm, AFAMgtT_LockedAftsNvm, AFAMgtT_stAftsNvm], written-variable=[AFAMgtT_ctLockRqAftsNvm, AFAMgtT_LockedAftsNvm, AFAMgtT_stAftsNvm]  # 01552_10_03370-AFAMgtT-A017(0)
        data receive point dr_Ext_nEng: data-element=R_Ext_nEng.Ext_nEng
        data send point dsp_Afts_bAcvRstAFA: data-element=P_Afts_bAcvRstAFA.Afts_bAcvRstAFA
        data send point dsp_AFAMgt_bAcvAdpRstDiag: data-element=P_AFAMgt_bAcvAdpRstDiag.AFAMgt_bAcvAdpRstDiag
      RE_AFAMgtT_003_TEV: read-variable=[AFAMgt_bStabFacStrtCor_irv, AFAMgt_bStabAirLdCor_irv, AFAMgt_tiDlyLstObsThd_irv, AFAMgt_tiCntStabAirMod_irv, AFAMgt_bIdcStabFuMod_irv, AFAMgt_bStabEOM_irv, AFAMgt_bStabEgdGear_irv, AFAMgt_tiCntStabFuMod_irv, AFAMgt_bIdcStabAirMod_irv, AFAMgt_bIdcStabRatOpEGR_irv, AFAMgt_bIdcNotDynCorPres_irv, AFAMgt_bInhAirModTmp_irv], written-variable=[AFAMgt_tiDlyLstObsThd_irv, AFAMgt_bEveRstStabChk_irv, AFAMgt_tiCntStabAirMod_irv, AFAMgt_bIdcStabFuMod_irv, AFAMgt_tiCntStabFuMod_irv, AFAMgt_bIdcStabAirMod_irv, AFAMgt_bInhAirModTmp_irv]  # 01552_10_03370-AFAMgtT-A003(3)
        26 x data receive point:
          dr_EngM_rTotLdExCor: data-element=R_EngM_rTotLdExCor.EngM_rTotLdExCor
          drp_Afts_bAcvRstAFA: data-element=R_Afts_bAcvRstAFA.Afts_bAcvRstAFA
          dr_Blby_bIdcWoutBlbyCnd: data-element=R_Blby_bIdcWoutBlbyCnd.Blby_bIdcWoutBlbyCnd
          dr_AFA_bAuthClsCanPurg: data-element=R_AFA_bAuthClsCanPurg.AFA_bAuthClsCanPurg
          dr_CanPurg_concFuStmEstim: data-element=R_CanPurg_concFuStmEstim.CanPurg_concFuStmEstim
          dr_AFA_rTotLdCorLstObs: data-element=R_AFA_rTotLdCorLstObs.AFA_rTotLdCorLstObs
          dr_Ext_tDsThrMes: data-element=R_Ext_tDsThrMes.Ext_tDsThrMes
          dr_InjSys_bAcvFuCll: data-element=R_InjSys_bAcvFuCll.InjSys_bAcvFuCll
          dr_EngM_rltMassAirScvCor: data-element=R_EngM_rltMassAirScvCor.EngM_rltMassAirScvCor
          dr_UsThrM_pAirExt: data-element=R_UsThrM_pAirExt.UsThrM_pAirExt
          dr_GSM_bAcvAFAAdp: data-element=R_GSM_bAcvAFAAdp.GSM_bAcvAFAAdp
          dr_AFA_bIdcCohLstObs: data-element=R_AFA_bIdcCohLstObs.AFA_bIdcCohLstObs
          dr_AFAMgt_bInhAFA: data-element=R_AFAMgt_bInhAFA.AFAMgt_bInhAFA
          dr_CanPurg_concFuStmErr: data-element=R_CanPurg_concFuStmErr.CanPurg_concFuStmErr
          dr_EngM_rDeltaLdInjPha: data-element=R_EngM_rDeltaLdInjPha.EngM_rDeltaLdInjPha
          dr_AFA_noObsDone: data-element=R_AFA_noObsDone.AFA_noObsDone
          dr_InjrM_prm_pDifInjr: data-element=R_InjrM_prm_pDifInjr.InjrM_prm_pDifInjr
          dr_AFA_tiDlyLstObs: data-element=R_AFA_tiDlyLstObs.AFA_tiDlyLstObs
          dr_AFA_nEngLstObs: data-element=R_AFA_nEngLstObs.AFA_nEngLstObs
          dr_AFA_noAdpEfc: data-element=R_AFA_noAdpEfc.AFA_noAdpEfc
          dr_Ext_tCoMes: data-element=R_Ext_tCoMes.Ext_tCoMes
          dr_InjrSys_prm_tiInj: data-element=R_InjrSys_prm_tiInj.InjrSys_prm_tiInj
          dr_Ext_nEng: data-element=R_Ext_nEng.Ext_nEng
          dr_Ext_pDsThrMesSI: data-element=R_Ext_pDsThrMesSI.Ext_pDsThrMesSI
          dr_FARSp_rMixtCylSp: data-element=R_FARSp_rMixtCylSp.FARSp_rMixtCylSp
          dr_InjrM_prm_facCorGainLnr: data-element=R_InjrM_prm_facCorGainLnr.InjrM_prm_facCorGainLnr
        8 x data send point:
          ds_AFAMgt_bAdpClcRstReq: data-element=P_AFAMgt_bAdpClcRstReq.AFAMgt_bAdpClcRstReq
          ds_AFAMgt_bInhAFA: data-element=P_AFAMgt_bInhAFA.AFAMgt_bInhAFA
          ds_AFAMgt_bIdcTmpObsCnd: data-element=P_AFAMgt_bIdcTmpObsCnd.AFAMgt_bIdcTmpObsCnd
          ds_AFAMgt_bAdpObsReq: data-element=P_AFAMgt_bAdpObsReq.AFAMgt_bAdpObsReq
          ds_AFAMgt_bAuthAdpReq: data-element=P_AFAMgt_bAuthAdpReq.AFAMgt_bAuthAdpReq
          ds_AFAMgt_bAcvAdpRstDiag: data-element=P_AFAMgt_bAcvAdpRstDiag.AFAMgt_bAcvAdpRstDiag
          ds_AFAMgt_bAdpEfcReq: data-element=P_AFAMgt_bAdpEfcReq.AFAMgt_bAdpEfcReq
          ds_AFAMgt_bIdcInjrMdlCnd: data-element=P_AFAMgt_bIdcInjrMdlCnd.AFAMgt_bIdcInjrMdlCnd
        6 x sync call:
          SC_FRM_bActAFAAdpRst: operation=R_FRM_bActAFAAdpRst.GetFunctionPermission
          SC_FRM_bActAFAInjGainRst: operation=R_FRM_bActAFAInjGainRst.GetFunctionPermission
          scp_SetEventStatus: operation=R_AFAMgt_ObsAdp.SetEventStatus
          SC_FRM_bInhAFAObsAdp: operation=R_FRM_bInhAFAObsAdp.GetFunctionPermission
          SC_FRM_bInhAFA: operation=R_FRM_bInhAFA.GetFunctionPermission
          SC_FRM_bInhInMNomMod: operation=R_FRM_bInhInMNomMod.GetFunctionPermission
      RE_AFAMgtT_001_MSE  # 01552_10_03370-AFAMgtT-A001(0)
        6 x data send point:
          ds_AFAMgt_bAuthAdpReq: data-element=P_AFAMgt_bAuthAdpReq.AFAMgt_bAuthAdpReq
          ds_AFAMgt_bInhAFA: data-element=P_AFAMgt_bInhAFA.AFAMgt_bInhAFA
          ds_AFAMgt_bAdpEfcReq: data-element=P_AFAMgt_bAdpEfcReq.AFAMgt_bAdpEfcReq
          ds_AFAMgt_bAdpObsReq: data-element=P_AFAMgt_bAdpObsReq.AFAMgt_bAdpObsReq
          ds_AFAMgt_bIdcTmpObsCnd: data-element=P_AFAMgt_bIdcTmpObsCnd.AFAMgt_bIdcTmpObsCnd
          ds_AFAMgt_bIdcInjrMdlCnd: data-element=P_AFAMgt_bIdcInjrMdlCnd.AFAMgt_bIdcInjrMdlCnd
      RE_AFAMgtT_AftrsInit: written-variable=[AFAMgtT_LockedAftsNvm, AFAMgtT_stAftsNvm, AFAMgtT_ctLockRqAftsNvm, AFAMgtT_stRstNvmRtn, AFAMgtT_IDAftsNvm]  # 01552_10_03370-AFAMgtT-A018(0)
        data send point dsp_Afts_bAcvRstAFA: data-element=P_Afts_bAcvRstAFA.Afts_bAcvRstAFA
      RE_AFAMgtT_007_TEV: read-variable=[AFAMgt_tiCntStabRatOpEGR_irv, AFAMgt_noEgdGearCordHld_irv, AFAMgt_rEGRMax_irv, AFAMgt_tiCntStabEOM_irv, AFAMgt_tiCntStabFacStrt_irv, AFAMgt_rAirLdMax_irv, AFAMgt_tiCntNotDynCorPres_irv, AFAMgt_rEGRMin_irv, AFAMgt_tiCntStabAirLd_irv, AFAMgt_tiCntStabEgdGear_irv, AFAMgt_bTranModHld_irv, AFAMgt_bEveRstStabChk_irv, AFAMgt_rAirLdMin_irv], written-variable=[AFAMgt_bStabEOM_irv, AFAMgt_tiCntStabRatOpEGR_irv, AFAMgt_noEgdGearCordHld_irv, AFAMgt_rEGRMax_irv, AFAMgt_bIdcNotDynCorPres_irv, AFAMgt_bStabFacStrtCor_irv, AFAMgt_bIdcStabRatOpEGR_irv, AFAMgt_tiCntStabEOM_irv, AFAMgt_tiCntStabFacStrt_irv, AFAMgt_bStabEgdGear_irv, AFAMgt_rAirLdMax_irv, AFAMgt_tiCntNotDynCorPres_irv, AFAMgt_rEGRMin_irv, AFAMgt_tiCntStabAirLd_irv, AFAMgt_bStabAirLdCor_irv, AFAMgt_tiCntStabEgdGear_irv, AFAMgt_bTranModHld_irv, AFAMgt_rAirLdMin_irv]  # 01552_10_03370-AFAMgtT-A007(0)
        8 x data receive point:
          dr_InjSys_prm_facStrtCorCyl: data-element=R_InjSys_prm_facStrtCorCyl.InjSys_prm_facStrtCorCyl
          dr_AFAMgt_bInhAFA: data-element=R_AFAMgt_bInhAFA.AFAMgt_bInhAFA
          dr_InM_pDynCorPres: data-element=R_InM_pDynCorPres.InM_pDynCorPres
          dr_EngM_rAirLdCor: data-element=R_EngM_rAirLdCor.EngM_rAirLdCor
          dr_EGRSys_rEGRReq: data-element=R_EGRSys_rEGRReq.EGRSys_rEGRReq
          dr_EOM_bTranMod: data-element=R_EOM_bTranMod.EOM_bTranMod
          dr_EGRVlv_stEGRMod: data-element=R_EGRVlv_stEGRMod.EGRVlv_stEGRMod
          dr_CoPt_noEgdGearCord: data-element=R_CoPt_noEgdGearCord.CoPt_noEgdGearCord
      RE_AFAMgtT_AftsNvmRDL  # 01552_10_03370-AFAMgtT-A012(0)
      RE_AFAMgtT_002_MSE: written-variable=AFAMgt_tiDlyLstObsThd_irv  # 01552_10_03370-AFAMgtT-A002(4)
        data send point ds_AFAMgt_bAcvAdpRstDiag: data-element=P_AFAMgt_bAcvAdpRstDiag.AFAMgt_bAcvAdpRstDiag
        data send point ds_AFAMgt_bAdpOfsRstReq: data-element=P_AFAMgt_bAdpOfsRstReq.AFAMgt_bAdpOfsRstReq
        data send point ds_AFAMgt_bAdpClcRstReq: data-element=P_AFAMgt_bAdpClcRstReq.AFAMgt_bAdpClcRstReq
        sync call SC_FRM_bAcvAdpValRstReq: operation=R_FRM_bAcvAdpValRstReq.GetFunctionPermission
        sync call SC_FRM_bAcvAdpClcStRstReq: operation=R_FRM_bAcvAdpClcStRstReq.GetFunctionPermission
  swc implementation Imp_AFAMgtT: programming-language=C, behavior=IB_AFAMgtT
    code-descriptors:
      code CodeDescriptor: type=SRC
        52 x xfile:
          AFAMgtT_F04_check_petrol_mode_stability_c: url=AFAMgtT_F04_check_petrol_mode_stability.c
          AFAMgtT_import_h: url=AFAMgtT_import.h
          AFAMgtT_F01_init_adaptation_manager_private_h: url=AFAMgtT_F01_init_adaptation_manager_private.h
          AFAMgtT_Init_h: url=AFAMgtT_Init.h
          AFAMgtT_c: url=AFAMgtT.c
          AFAMgtT_F01_adaptation_observations_delay_import_h: url=AFAMgtT_F01_adaptation_observations_delay_import.h
          AFAMgtT_F01_adaptation_observations_delay_c: url=AFAMgtT_F01_adaptation_observations_delay.c
          AFAMgtT_F01_AFAAdpCndChk_types_h: url=AFAMgtT_F01_AFAAdpCndChk_types.h
          AFAMgtT_F03_check_air_mode_stability_h: url=AFAMgtT_F03_check_air_mode_stability.h
          AFAMgtT_Version_c: url=AFAMgtT_Version.c
          AFAMgtT_F02_check_stability_SdlMid_c: url=AFAMgtT_F02_check_stability_SdlMid.c
          AFAMgtT_private_h: url=AFAMgtT_private.h
          AFAMgtT_F02_command_observation_types_h: url=AFAMgtT_F02_command_observation_types.h
          AFAMgtT_F01_init_adaptation_manager_types_h: url=AFAMgtT_F01_init_adaptation_manager_types.h
          AFAMgtT_h: url=AFAMgtT.h
          AFAMgtT_Init_private_h: url=AFAMgtT_Init_private.h
          AFAMgtT_F02_check_stability_SdlMid_import_h: url=AFAMgtT_F02_check_stability_SdlMid_import.h
          AFAMgtT_F01_AFAAdpCndChk_c: url=AFAMgtT_F01_AFAAdpCndChk.c
          AFAMgtT_Init_c: url=AFAMgtT_Init.c
          AFAMgtT_F02_check_stability_SdlMid_h: url=AFAMgtT_F02_check_stability_SdlMid.h
          AFAMgtT_nvm_c: url=AFAMgtT_nvm.c
          AFAMgtT_F01_init_adaptation_manager_c: url=AFAMgtT_F01_init_adaptation_manager.c
          AFAMgtT_F01_AFAAdpCndChk_import_h: url=AFAMgtT_F01_AFAAdpCndChk_import.h
          AFAMgtT_F02_command_observation_private_h: url=AFAMgtT_F02_command_observation_private.h
          AFAMgtT_F04_check_petrol_mode_stability_types_h: url=AFAMgtT_F04_check_petrol_mode_stability_types.h
          AFAMgtT_F04_check_petrol_mode_stability_private_h: url=AFAMgtT_F04_check_petrol_mode_stability_private.h
          AFAMgtT_nvm_h: url=AFAMgtT_nvm.h
          AFAMgtT_Aftrs_h: url=AFAMgtT_Aftrs.h
          AFAMgtT_F01_init_adaptation_manager_import_h: url=AFAMgtT_F01_init_adaptation_manager_import.h
          AFAMgtT_MemMap_h: url=AFAMgtT_MemMap.h
          AFAMgtT_F03_check_air_mode_stability_types_h: url=AFAMgtT_F03_check_air_mode_stability_types.h
          AFAMgtT_F02_command_observation_h: url=AFAMgtT_F02_command_observation.h
          AFAMgtT_F04_check_petrol_mode_stability_h: url=AFAMgtT_F04_check_petrol_mode_stability.h
          AFAMgtT_F02_check_stability_SdlMid_private_h: url=AFAMgtT_F02_check_stability_SdlMid_private.h
          AFAMgtT_F01_AFAAdpCndChk_h: url=AFAMgtT_F01_AFAAdpCndChk.h
          AFAMgtT_Version_h: url=AFAMgtT_Version.h
          AFAMgtT_F02_check_stability_SdlMid_types_h: url=AFAMgtT_F02_check_stability_SdlMid_types.h
          AFAMgtT_types_h: url=AFAMgtT_types.h
          AFAMgtT_F01_AFAAdpCndChk_private_h: url=AFAMgtT_F01_AFAAdpCndChk_private.h
          AFAMgtT_F01_adaptation_observations_delay_h: url=AFAMgtT_F01_adaptation_observations_delay.h
          AFAMgtT_F03_check_air_mode_stability_import_h: url=AFAMgtT_F03_check_air_mode_stability_import.h
          AFAMgtT_F01_init_adaptation_manager_h: url=AFAMgtT_F01_init_adaptation_manager.h
          AFAMgtT_F03_check_air_mode_stability_c: url=AFAMgtT_F03_check_air_mode_stability.c
          AFAMgtT_Init_types_h: url=AFAMgtT_Init_types.h
          AFAMgtT_Def_c: url=AFAMgtT_Def.c
          AFAMgtT_F02_command_observation_c: url=AFAMgtT_F02_command_observation.c
          AFAMgtT_F01_adaptation_observations_delay_types_h: url=AFAMgtT_F01_adaptation_observations_delay_types.h
          AFAMgtT_F03_check_air_mode_stability_private_h: url=AFAMgtT_F03_check_air_mode_stability_private.h
          AFAMgtT_Aftrs_c: url=AFAMgtT_Aftrs.c
          AFAMgtT_F02_command_observation_import_h: url=AFAMgtT_F02_command_observation_import.h
          AFAMgtT_F01_adaptation_observations_delay_private_h: url=AFAMgtT_F01_adaptation_observations_delay_private.h
          AFAMgtT_F04_check_petrol_mode_stability_import_h: url=AFAMgtT_F04_check_petrol_mode_stability_import.h
package /Components/SWC_AFAMgtT/AFAMgtT_IRVDatatypes
  12 x boolean type, all with base-type=boolean:
    DT_AFAMgt_bEveRstStabChk_irv
    DT_AFAMgt_bIdcNotDynCorPres_irv
    DT_AFAMgt_bIdcStabAirMod_irv
    DT_AFAMgt_bIdcStabFuMod_irv
    DT_AFAMgt_bIdcStabRatOpEGR_irv
    DT_AFAMgt_bInhAirModTmp_irv
    DT_AFAMgt_bStabAirLdCor_irv
    DT_AFAMgt_bStabEgdGear_irv
    DT_AFAMgt_bStabEOM_irv
    DT_AFAMgt_bStabFacStrtCor_irv
    DT_AFAMgt_bTranModHld_irv
    DT_AFAMgtT_LockedAftsNvm
  18 x integer type, all with lower-limit=0:
    DT_AFAMgt_noEgdGearCordHld_irv: base-type=uint8, upper-limit=255
    DT_AFAMgt_rAirLdMax_irv: base-type=uint16, upper-limit=65535
    DT_AFAMgt_rAirLdMin_irv: base-type=uint16, upper-limit=65535
    DT_AFAMgt_rEGRMax_irv: base-type=uint8, upper-limit=255
    DT_AFAMgt_rEGRMin_irv: base-type=uint8, upper-limit=255
    DT_AFAMgt_tiCntNotDynCorPres_irv: base-type=uint32, upper-limit=4294967295
    DT_AFAMgt_tiCntStabAirLd_irv: base-type=uint32, upper-limit=4294967295
    DT_AFAMgt_tiCntStabAirMod_irv: base-type=uint32, upper-limit=4294967295
    DT_AFAMgt_tiCntStabEgdGear_irv: base-type=uint32, upper-limit=4294967295
    DT_AFAMgt_tiCntStabEOM_irv: base-type=uint32, upper-limit=4294967295
    DT_AFAMgt_tiCntStabFacStrt_irv: base-type=uint32, upper-limit=4294967295
    DT_AFAMgt_tiCntStabFuMod_irv: base-type=uint32, upper-limit=4294967295
    DT_AFAMgt_tiCntStabRatOpEGR_irv: base-type=uint32, upper-limit=4294967295
    DT_AFAMgt_tiDlyLstObsThd_irv: base-type=uint32, upper-limit=4294967295
    DT_AFAMgtT_ctLockRqAftsNvm: base-type=uint8, upper-limit=255
    DT_AFAMgtT_IDAftsNvm: base-type=uint8, upper-limit=255
    DT_AFAMgtT_stAftsNvm: base-type=uint8, upper-limit=255
    DT_AFAMgtT_stRstNvmRtn: base-type=uint32, upper-limit=4294967295
